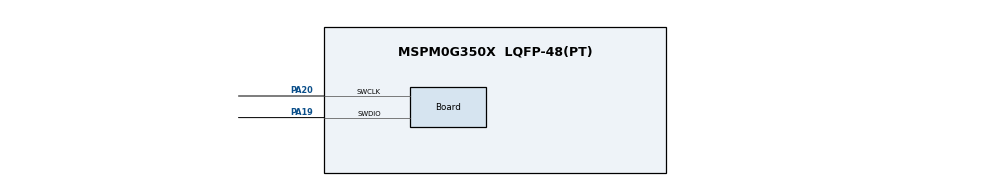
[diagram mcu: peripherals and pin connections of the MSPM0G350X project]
/**
 * @cliArgs --device "MSPM0G350X" --package "LQFP-48(PT)" --part "Default" --product "mspm0_sdk@2.01.00.03"
 * @versions {"tool":"1.20.0+3587"}
 */

/**
 * Import the modules used in this configuration.
 */
const GPIO          = scripting.addModule("/ti/driverlib/GPIO", {}, false);
const GPIO1         = GPIO.addInstance();
const SYSCTL        = scripting.addModule("/ti/driverlib/SYSCTL");
const ProjectConfig = scripting.addModule("/ti/project_config/ProjectConfig");

/**
 * Write custom configuration values to the imported modules.
 */
GPIO1.$name                              = "GPIO_OLED";
GPIO1.associatedPins.create(2);
GPIO1.associatedPins[0].initialValue     = "SET";
GPIO1.associatedPins[0].internalResistor = "PULL_UP";
GPIO1.associatedPins[0].assignedPort     = "PORTB";
GPIO1.associatedPins[0].assignedPin      = "6";
GPIO1.associatedPins[0].$name            = "SCL";
GPIO1.associatedPins[1].initialValue     = "SET";
GPIO1.associatedPins[1].internalResistor = "PULL_UP";
GPIO1.associatedPins[1].assignedPort     = "PORTB";
GPIO1.associatedPins[1].assignedPin      = "7";
GPIO1.associatedPins[1].$name            = "SDA";

const Board                       = scripting.addModule("/ti/driverlib/Board", {}, false);
Board.peripheral.$assign          = "DEBUGSS";
Board.peripheral.swclkPin.$assign = "PA20";
Board.peripheral.swdioPin.$assign = "PA19";

SYSCTL.forceDefaultClkConfig = true;
SYSCTL.peripheral.$assign    = "SYSCTL";

ProjectConfig.deviceSpin = "MSPM0G3507";
scripting.suppress("Migrating requires going through the Switch Board or Device menu in the Device View section\\.", ProjectConfig, "deviceSpin");

/**
 * Pinmux solution for unlocked pins/peripherals. This ensures that minor changes to the automatic solver in a future
 * version of the tool will not impact the pinmux you originally saw.  These lines can be completely deleted in order to
 * re-solve from scratch.
 */
GPIO1.associatedPins[0].pin.$suggestSolution = "PB6";
GPIO1.associatedPins[1].pin.$suggestSolution = "PB7";
